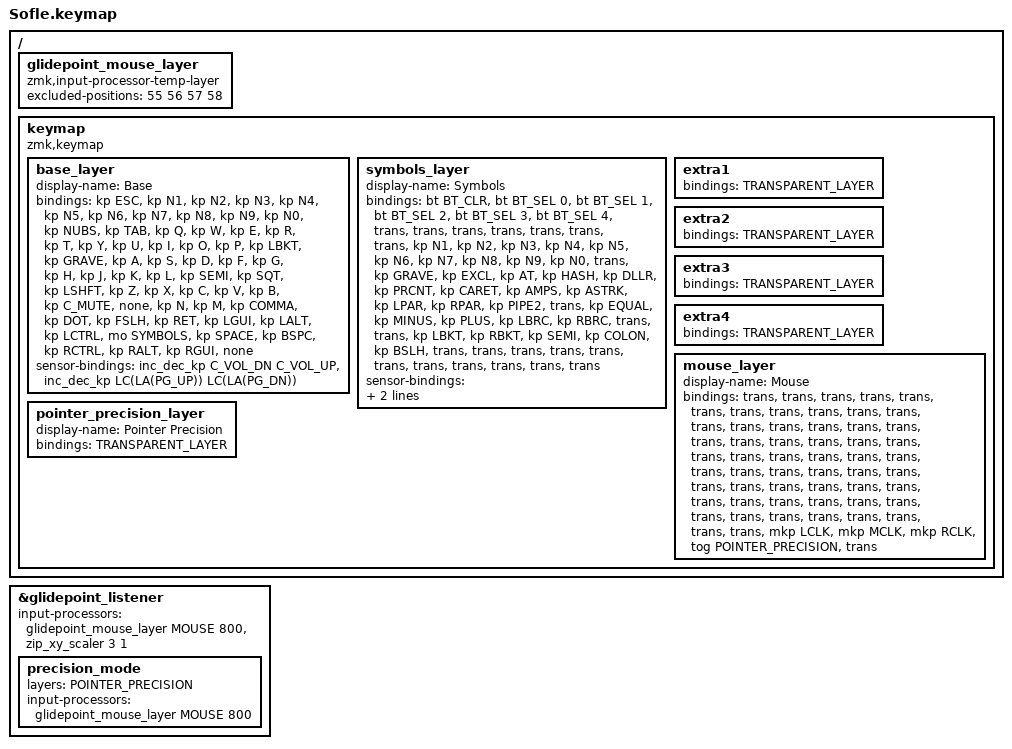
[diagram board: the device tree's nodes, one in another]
/*
 * Copyright (c) 2020 The ZMK Contributors
 *
 * SPDX-License-Identifier: MIT
 */

#include <behaviors.dtsi>
#include <dt-bindings/zmk/keys.h>
#include <dt-bindings/zmk/bt.h>
#include <dt-bindings/zmk/pointing.h>
#include <input/processors.dtsi>

#define BASE 0
#define SYMBOLS 1
#define MOUSE 6
#define POINTER_PRECISION 7

#define TRANSPARENT_LAYER \
    &trans &trans &trans &trans &trans &trans &trans &trans &trans &trans &trans &trans \
    &trans &trans &trans &trans &trans &trans &trans &trans &trans &trans &trans &trans \
    &trans &trans &trans &trans &trans &trans &trans &trans &trans &trans &trans &trans \
    &trans &trans &trans &trans &trans &trans &trans &trans &trans &trans &trans &trans &trans &trans \
    &trans &trans &trans &trans &trans &trans &trans &trans &trans &trans

&glidepoint_listener {
    input-processors = <&glidepoint_mouse_layer MOUSE 800>, <&zip_xy_scaler 3 1>;

    precision_mode {
        layers = <POINTER_PRECISION>;
        input-processors = <&glidepoint_mouse_layer MOUSE 800>;
    };
};

/ {
    glidepoint_mouse_layer: glidepoint_mouse_layer {
        compatible = "zmk,input-processor-temp-layer";
        #input-processor-cells = <2>;
        // Right thumb mouse buttons and speed toggle.
        excluded-positions = <55 56 57 58>;
    };

    keymap {
        compatible = "zmk,keymap";

        base_layer {
            display-name = "Base";
            bindings = <
&kp ESC   &kp N1 &kp N2   &kp N3   &kp N4      &kp N5                                  &kp N6    &kp N7    &kp N8    &kp N9   &kp N0   &kp NUBS
&kp TAB   &kp Q  &kp W    &kp E    &kp R       &kp T                                   &kp Y     &kp U     &kp I     &kp O    &kp P    &kp LBKT
&kp GRAVE &kp A  &kp S    &kp D    &kp F       &kp G                                   &kp H     &kp J     &kp K     &kp L    &kp SEMI &kp SQT
&kp LSHFT &kp Z  &kp X    &kp C    &kp V       &kp B       &kp C_MUTE  &none           &kp N     &kp M     &kp COMMA &kp DOT  &kp FSLH &kp RET
                 &kp LGUI &kp LALT &kp LCTRL   &mo SYMBOLS &kp SPACE   &kp BSPC        &kp RCTRL &kp RALT  &kp RGUI  &none
            >;
            sensor-bindings = <&inc_dec_kp C_VOL_DN C_VOL_UP &inc_dec_kp LC(LA(PG_UP)) LC(LA(PG_DN))>;
        };

        symbols_layer {
            display-name = "Symbols";
            bindings = <
&bt BT_CLR &bt BT_SEL 0 &bt BT_SEL 1 &bt BT_SEL 2 &bt BT_SEL 3 &bt BT_SEL 4             &trans    &trans   &trans    &trans    &trans   &trans
&trans     &kp N1       &kp N2       &kp N3       &kp N4       &kp N5                   &kp N6    &kp N7   &kp N8    &kp N9    &kp N0   &trans
&kp GRAVE  &kp EXCL     &kp AT       &kp HASH     &kp DLLR     &kp PRCNT                &kp CARET &kp AMPS &kp ASTRK &kp LPAR  &kp RPAR &kp PIPE2
&trans     &kp EQUAL    &kp MINUS    &kp PLUS     &kp LBRC     &kp RBRC  &trans  &trans &kp LBKT  &kp RBKT &kp SEMI  &kp COLON &kp BSLH &trans
                        &trans       &trans       &trans       &trans    &trans  &trans &trans    &trans   &trans    &trans
            >;
            sensor-bindings = <&inc_dec_kp LC(LA(PG_UP)) LC(LA(PG_DN)) &inc_dec_kp C_VOL_DN C_VOL_UP>;
        };

        extra1 {
            status = "okay";
            bindings = <TRANSPARENT_LAYER>;
        };

        extra2 {
            status = "okay";
            bindings = <TRANSPARENT_LAYER>;
        };

        extra3 {
            status = "okay";
            bindings = <TRANSPARENT_LAYER>;
        };

        extra4 {
            status = "okay";
            bindings = <TRANSPARENT_LAYER>;
        };

        // Keep the six existing Studio layer IDs and append the mouse layer.
        mouse_layer {
            display-name = "Mouse";
            bindings = <
&trans &trans &trans &trans &trans &trans &trans &trans &trans &trans &trans &trans
&trans &trans &trans &trans &trans &trans &trans &trans &trans &trans &trans &trans
&trans &trans &trans &trans &trans &trans &trans &trans &trans &trans &trans &trans
&trans &trans &trans &trans &trans &trans &trans &trans &trans &trans &trans &trans &trans &trans
&trans &trans &trans &trans &trans &mkp LCLK &mkp MCLK &mkp RCLK &tog POINTER_PRECISION &trans
            >;
        };

        pointer_precision_layer {
            display-name = "Pointer Precision";
            bindings = <TRANSPARENT_LAYER>;
        };
    };
};
